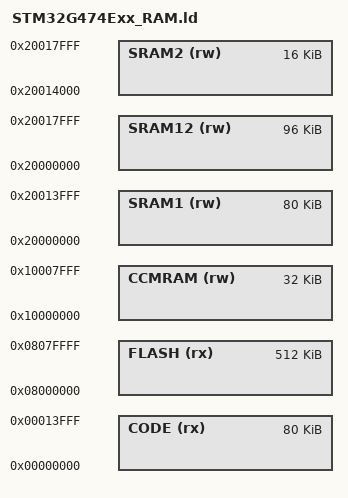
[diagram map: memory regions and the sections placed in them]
/* STM32G474Exx — Cat4, 512K flash, Hi-resolution line — run from RAM.
   Generated by narray from MEMORY.periph, DO NOT EDIT. */

MEMORY
{
  FLASH  (rx) : ORIGIN = 0x8000000, LENGTH = 512K
  CCMRAM (rw) : ORIGIN = 0x10000000, LENGTH = 32K  /* aliased at 0x20018000 */
  SRAM1  (rw) : ORIGIN = 0x20000000, LENGTH = 80K
  SRAM2  (rw) : ORIGIN = 0x20014000, LENGTH = 16K
  SRAM12 (rw) : ORIGIN = 0x20000000, LENGTH = 96K  /* SRAM1+SRAM2, contiguous */
  CODE   (rx) : ORIGIN = 0x00000000, LENGTH = 80K  /* boot alias: flash, then SRAM1 remapped */
}

REGION_ALIAS("TEXT", CODE);   /* code & vectors at the 0x0 alias      */
REGION_ALIAS("DATA", SRAM1);  /* code image + .data/.bss, physically  */
REGION_ALIAS("LOAD", FLASH);  /* the whole image is stored in flash   */
REGION_ALIAS("DMARAM", SRAM1);  /* NARRAY_DMABUF buffers */
REGION_ALIAS("SCRATCH", CCMRAM);  /* stack + crash record  */

_estack = ORIGIN(CCMRAM) + LENGTH(CCMRAM); /* top of stack */

INCLUDE devs.ld      /* peripheral addresses (narray) */
INCLUDE sections_ram.ld /* section layout (lib)          */
